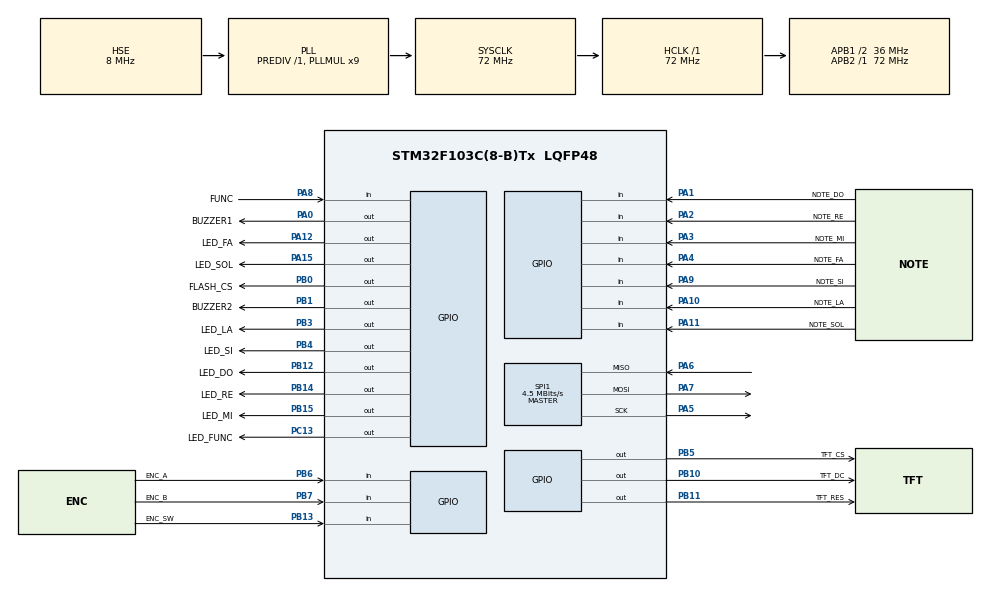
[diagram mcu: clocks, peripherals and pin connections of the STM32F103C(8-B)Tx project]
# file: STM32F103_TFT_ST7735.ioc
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Mcu.Family=STM32F1
Mcu.Name=STM32F103C(8-B)Tx
Mcu.Package=LQFP48
NVIC.PriorityGroup=NVIC_PRIORITYGROUP_4
PA5.Mode=Full_Duplex_Master
PA5.Signal=SPI1_SCK
PA6.Mode=Full_Duplex_Master
PA6.Signal=SPI1_MISO
PA7.Mode=Full_Duplex_Master
PA7.Signal=SPI1_MOSI
PA13.Mode=Serial_Wire
PA13.Signal=SYS_JTMS-SWDIO
PA14.Mode=Serial_Wire
PA14.Signal=SYS_JTCK-SWCLK
PA4.GPIO_Label=NOTE_FA
PA4.GPIO_PuPd=GPIO_PULLUP
PA4.Signal=GPIO_Input
PA1.GPIO_Label=NOTE_DO
PA1.GPIO_PuPd=GPIO_PULLUP
PA1.Signal=GPIO_Input
PA2.GPIO_Label=NOTE_RE
PA2.GPIO_PuPd=GPIO_PULLUP
PA2.Signal=GPIO_Input
PA3.GPIO_Label=NOTE_MI
PA3.GPIO_PuPd=GPIO_PULLUP
PA3.Signal=GPIO_Input
PA9.GPIO_Label=NOTE_SI
PA9.GPIO_PuPd=GPIO_PULLUP
PA9.Signal=GPIO_Input
PA10.GPIO_Label=NOTE_LA
PA10.GPIO_PuPd=GPIO_PULLUP
PA10.Signal=GPIO_Input
PB0.GPIO_Label=FLASH_CS
PB0.PinState=GPIO_PIN_SET
PB0.Signal=GPIO_Output
PB12.GPIO_Label=LED_DO
PB12.PinState=GPIO_PIN_RESET
PB12.Signal=GPIO_Output
PA0.GPIO_Label=BUZZER1
PA0.PinState=GPIO_PIN_RESET
PA0.Signal=GPIO_Output
PB1.GPIO_Label=BUZZER2
PB1.PinState=GPIO_PIN_SET
PB1.Signal=GPIO_Output
PA8.GPIO_Label=FUNC
PA8.GPIO_PuPd=GPIO_PULLUP
PA8.Signal=GPIO_Input
PB14.GPIO_Label=LED_RE
PB14.PinState=GPIO_PIN_RESET
PB14.Signal=GPIO_Output
PB15.GPIO_Label=LED_MI
PB15.PinState=GPIO_PIN_RESET
PB15.Signal=GPIO_Output
PA12.GPIO_Label=LED_FA
PA12.PinState=GPIO_PIN_RESET
PA12.Signal=GPIO_Output
PA15.GPIO_Label=LED_SOL
PA15.PinState=GPIO_PIN_RESET
PA15.Signal=GPIO_Output
PB3.GPIO_Label=LED_LA
PB3.PinState=GPIO_PIN_RESET
PB3.Signal=GPIO_Output
PB4.GPIO_Label=LED_SI
PB4.PinState=GPIO_PIN_RESET
PB4.Signal=GPIO_Output
PC13.GPIO_Label=LED_FUNC
PC13.PinState=GPIO_PIN_RESET
PC13.Signal=GPIO_Output
PB5.GPIO_Label=TFT_CS
PB5.PinState=GPIO_PIN_SET
PB5.Signal=GPIO_Output
PB10.GPIO_Label=TFT_DC
PB10.PinState=GPIO_PIN_SET
PB10.Signal=GPIO_Output
PB11.GPIO_Label=TFT_RES
PB11.PinState=GPIO_PIN_SET
PB11.Signal=GPIO_Output
PA11.GPIO_Label=NOTE_SOL
PA11.GPIO_PuPd=GPIO_PULLUP
PA11.Signal=GPIO_Input
PB6.GPIO_Label=ENC_A
PB6.GPIO_PuPd=GPIO_PULLUP
PB6.Signal=GPIO_Input
PB7.GPIO_Label=ENC_B
PB7.GPIO_PuPd=GPIO_PULLUP
PB7.Signal=GPIO_Input
PB13.GPIO_Label=ENC_SW
PB13.GPIO_PuPd=GPIO_PULLUP
PB13.Signal=GPIO_Input
PD0-OSC_IN.Mode=HSE-External-Oscillator
PD0-OSC_IN.Signal=RCC_OSC_IN
PD1-OSC_OUT.Mode=HSE-External-Oscillator
PD1-OSC_OUT.Signal=RCC_OSC_OUT
ProjectManager.HeapSize=0x200
ProjectManager.StackSize=0x400
ProjectManager.TargetToolchain=Makefile
RCC.AHBFreq_Value=72000000
RCC.APB1CLKDivider=RCC_HCLK_DIV2
RCC.APB1Freq_Value=36000000
RCC.APB1TimFreq_Value=72000000
RCC.APB2Freq_Value=72000000
RCC.APB2TimFreq_Value=72000000
RCC.HCLKFreq_Value=72000000
RCC.PLLMUL=RCC_PLL_MUL9
RCC.PLLSourceVirtual=RCC_PLLSOURCE_HSE
RCC.SYSCLKFreq_VALUE=72000000
RCC.SYSCLKSource=RCC_SYSCLKSOURCE_PLLCLK
RCC.USBFreq_Value=72000000
SPI1.BaudRatePrescaler=SPI_BAUDRATEPRESCALER_16
SPI1.CalculateBaudRate=4.5 MBits/s
SPI1.Direction=SPI_DIRECTION_2LINES
SPI1.Mode=SPI_MODE_MASTER
SPI1.VirtualType=VM_MASTER
board=custom

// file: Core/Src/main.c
/* USER CODE BEGIN Header */
/**
  ******************************************************************************
  * @file           : main.c
  * @brief          : STM32F103C8T6 + 1.8" ST7735 TFT: SmartTone UI
  ******************************************************************************
  * @attention
  *
  * Copyright (c) 2026 STMicroelectronics.
  * All rights reserved.
  *
  * This software is licensed under terms that can be found in the LICENSE file
  * in the root directory of this software component.
  * If no LICENSE file comes with this software, it is provided AS-IS.
  *
  ******************************************************************************
  */
/* USER CODE END Header */
#include "main.h"

/* USER CODE BEGIN Includes */
#include "bsp_tft.h"
#include "bsp_encoder.h"
#include "bsp_func.h"
#include "bsp_notes.h"
#include "bsp_audio_tim.h"
#include "audio.h"
#include "audio_pwm.h"
#include "ui_page.h"
#include "record.h"
#include "boot_logo.h"
#include "rhythm_game.h"
#include "melody_maker.h"
/* USER CODE END Includes */

SPI_HandleTypeDef hspi1;

void SystemClock_Config(void);
static void MX_GPIO_Init(void);
static void MX_SPI1_Init(void);

int main(void)
{

  /* MCU Configuration--------------------------------------------------------*/

  /* Reset of all peripherals, initializes the Flash interface and the Systick. */
  HAL_Init();

  /* Configure the system clock */
  SystemClock_Config();

  /* Initialize all configured peripherals */
  MX_GPIO_Init();
  MX_SPI1_Init();
  /* USER CODE BEGIN 2 */
  /* 先把背光点亮，面板上电期间状态才确定；不依赖按键。 */
  tft_backlight_init();
  tft_set_brightness(5U);
  HAL_Delay(120);   /* 等面板电源稳定，冷启动时这一步很重要 */

  if (!tft_init(&hspi1)) {
    /* 仍然失败就再降速到 1.125 MHz 重试一次 */
    __HAL_SPI_DISABLE(&hspi1);
    hspi1.Init.BaudRatePrescaler = SPI_BAUDRATEPRESCALER_64;
    (void)HAL_SPI_Init(&hspi1);
    (void)tft_init(&hspi1);
  }
  AudioTim_Init();
  Audio_Init();
  Audio_AllOff();   /* 上电保险：任何残留声部立即静音，杜绝长响 */
  bsp_notes_init();
  rhythm_game_init();
  bsp_encoder_init();
  bsp_func_init();
  record_init(&hspi1);

  /* 外设初始化完成后先显示启动图；主菜单延迟到 5 s 启动流程结束后绘制。 */
  boot_logo_start();
  /* USER CODE END 2 */

  /* Infinite loop */
  /* USER CODE BEGIN WHILE */
  while (1)
  {
    uint32_t now = HAL_GetTick();

    /* 启动图期间只推进 SysTick 计时，不扫描编码器、FUNC 或音符按键。 */
    if (boot_logo_active()) {
      if (boot_logo_tick(now)) {
        ui_page_init();
      }
      continue;
    }

    Audio_Envelope_Tick();
    Metronome_Tick();
    Song_Tick();
    Drum_Tick();
    if (!melody_maker_active() && !AudioPwm_PcmActive()) { bsp_notes_poll(now); }
    bsp_encoder_poll(now);
    bsp_func_poll(now);
    ui_page_tick(now);

    bsp_encoder_event_t event;
    while (bsp_encoder_take_event(&event)) {
      ui_page_handle_event(event);
    }
    switch (bsp_func_take_event()) {
      case BSP_FUNC_EVENT_SHORT: ui_page_handle_func();      break;
      case BSP_FUNC_EVENT_LONG:  ui_page_handle_func_long(); break;
      default: break;
    }
    /* USER CODE END WHILE */

  }
}

void SystemClock_Config(void)
{
  RCC_OscInitTypeDef RCC_OscInitStruct = {0};
  RCC_ClkInitTypeDef RCC_ClkInitStruct = {0};

  /** Initializes the RCC Oscillators according to the specified parameters
  * in the RCC_OscInitTypeDef structure.
  */
  RCC_OscInitStruct.OscillatorType = RCC_OSCILLATORTYPE_HSE;
  RCC_OscInitStruct.HSEState = RCC_HSE_ON;
  RCC_OscInitStruct.HSEPredivValue = RCC_HSE_PREDIV_DIV1;
  RCC_OscInitStruct.HSIState = RCC_HSI_ON;
  RCC_OscInitStruct.PLL.PLLState = RCC_PLL_ON;
  RCC_OscInitStruct.PLL.PLLSource = RCC_PLLSOURCE_HSE;
  RCC_OscInitStruct.PLL.PLLMUL = RCC_PLL_MUL9;
  if (HAL_RCC_OscConfig(&RCC_OscInitStruct) != HAL_OK)
  {
    Error_Handler();
  }

  /** Initializes the CPU, AHB and APB buses clocks
  */
  RCC_ClkInitStruct.ClockType = RCC_CLOCKTYPE_HCLK|RCC_CLOCKTYPE_SYSCLK
                              |RCC_CLOCKTYPE_PCLK1|RCC_CLOCKTYPE_PCLK2;
  RCC_ClkInitStruct.SYSCLKSource = RCC_SYSCLKSOURCE_PLLCLK;
  RCC_ClkInitStruct.AHBCLKDivider = RCC_SYSCLK_DIV1;
  RCC_ClkInitStruct.APB1CLKDivider = RCC_HCLK_DIV2;
  RCC_ClkInitStruct.APB2CLKDivider = RCC_HCLK_DIV1;

  if (HAL_RCC_ClockConfig(&RCC_ClkInitStruct, FLASH_LATENCY_2) != HAL_OK)
  {
    Error_Handler();
  }
}

static void MX_SPI1_Init(void)
{
  hspi1.Instance = SPI1;
  hspi1.Init.Mode = SPI_MODE_MASTER;
  hspi1.Init.Direction = SPI_DIRECTION_2LINES;
  hspi1.Init.DataSize = SPI_DATASIZE_8BIT;
  hspi1.Init.CLKPolarity = SPI_POLARITY_LOW;
  hspi1.Init.CLKPhase = SPI_PHASE_1EDGE;
  hspi1.Init.NSS = SPI_NSS_SOFT;
  hspi1.Init.BaudRatePrescaler = SPI_BAUDRATEPRESCALER_32; /* 72 MHz / 32 = 2.25 MHz，杜邦线上更稳 */
  hspi1.Init.FirstBit = SPI_FIRSTBIT_MSB;
  hspi1.Init.TIMode = SPI_TIMODE_DISABLE;
  hspi1.Init.CRCCalculation = SPI_CRCCALCULATION_DISABLE;
  hspi1.Init.CRCPolynomial = 10;
  if (HAL_SPI_Init(&hspi1) != HAL_OK)
  {
    Error_Handler();
  }
}

static void MX_GPIO_Init(void)
{
  GPIO_InitTypeDef GPIO_InitStruct = {0};

  /* GPIO Ports Clock Enable */
  __HAL_RCC_GPIOA_CLK_ENABLE();
  __HAL_RCC_GPIOB_CLK_ENABLE();
  __HAL_RCC_GPIOC_CLK_ENABLE();

  /* PA15/PB3/PB4 作为 LED，需要关闭 JTAG、保留 SWD。 */
  __HAL_AFIO_REMAP_SWJ_NOJTAG();

  /* TFT 控制脚初始为高电平，DC 在驱动内部发送命令时再拉低。 */
  HAL_GPIO_WritePin(GPIOB, TFT_CS_Pin | TFT_DC_Pin | TFT_RES_Pin, GPIO_PIN_SET);
  /* W25Q64 独立片选 PB0，空闲保持高电平。 */
  HAL_GPIO_WritePin(W25Q64_CS_GPIO_Port, W25Q64_CS_Pin, GPIO_PIN_SET);
  /* 蜂鸣器和 LED 初始关闭。 */
  HAL_GPIO_WritePin(GPIOA, BUZZER1_Pin | LED_FA_Pin | LED_SOL_Pin, GPIO_PIN_RESET);
  HAL_GPIO_WritePin(GPIOB,
                    BUZZER2_Pin | LED_DO_Pin | LED_RE_Pin | LED_MI_Pin |
                    LED_LA_Pin | LED_SI_Pin, GPIO_PIN_RESET);
  HAL_GPIO_WritePin(GPIOC, LED_FUNC_Pin, GPIO_PIN_RESET);

  /*Configure GPIO pins : TFT_CS_Pin TFT_DC_Pin TFT_RES_Pin */
  GPIO_InitStruct.Pin = TFT_CS_Pin | TFT_DC_Pin | TFT_RES_Pin;
  GPIO_InitStruct.Mode = GPIO_MODE_OUTPUT_PP;
  GPIO_InitStruct.Pull = GPIO_NOPULL;
  GPIO_InitStruct.Speed = GPIO_SPEED_FREQ_HIGH;
  HAL_GPIO_Init(GPIOB, &GPIO_InitStruct);

  /* W25Q64 片选 PB0，推挽输出，初始高电平。 */
  GPIO_InitStruct.Pin = W25Q64_CS_Pin;
  GPIO_InitStruct.Mode = GPIO_MODE_OUTPUT_PP;
  GPIO_InitStruct.Pull = GPIO_NOPULL;
  GPIO_InitStruct.Speed = GPIO_SPEED_FREQ_HIGH;
  HAL_GPIO_Init(W25Q64_CS_GPIO_Port, &GPIO_InitStruct);

  /* 两路蜂鸣器输出，初始低电平。 */
  GPIO_InitStruct.Pin = BUZZER1_Pin | LED_FA_Pin | LED_SOL_Pin;
  GPIO_InitStruct.Mode = GPIO_MODE_OUTPUT_PP;
  GPIO_InitStruct.Pull = GPIO_NOPULL;
  GPIO_InitStruct.Speed = GPIO_SPEED_FREQ_HIGH;
  HAL_GPIO_Init(GPIOA, &GPIO_InitStruct);

  GPIO_InitStruct.Pin = BUZZER2_Pin | LED_DO_Pin | LED_RE_Pin |
                        LED_MI_Pin | LED_LA_Pin | LED_SI_Pin;
  GPIO_InitStruct.Mode = GPIO_MODE_OUTPUT_PP;
  GPIO_InitStruct.Pull = GPIO_NOPULL;
  GPIO_InitStruct.Speed = GPIO_SPEED_FREQ_HIGH;
  HAL_GPIO_Init(GPIOB, &GPIO_InitStruct);

  GPIO_InitStruct.Pin = LED_FUNC_Pin;
  GPIO_InitStruct.Mode = GPIO_MODE_OUTPUT_PP;
  GPIO_InitStruct.Pull = GPIO_NOPULL;
  GPIO_InitStruct.Speed = GPIO_SPEED_FREQ_LOW;
  HAL_GPIO_Init(GPIOC, &GPIO_InitStruct);

  /* EC11 A=PB6、B=PB7、按键=PB13：上拉输入，公共端接 GND。 */
  GPIO_InitStruct.Pin = ENC_A_Pin | ENC_B_Pin | ENC_SW_Pin;
  GPIO_InitStruct.Mode = GPIO_MODE_INPUT;
  GPIO_InitStruct.Pull = GPIO_PULLUP;
  HAL_GPIO_Init(GPIOB, &GPIO_InitStruct);

  /* FUNC 按键 PA8：上拉输入，按下接地。 */
  GPIO_InitStruct.Pin = FUNC_Pin;
  GPIO_InitStruct.Mode = GPIO_MODE_INPUT;
  GPIO_InitStruct.Pull = GPIO_PULLUP;
  HAL_GPIO_Init(FUNC_GPIO_Port, &GPIO_InitStruct);

  /* 7 个音符按键：PA1/2/3/4/11/10/9，上拉输入，按下为低。 */
  GPIO_InitStruct.Pin = NOTE_DO_Pin | NOTE_RE_Pin | NOTE_MI_Pin |
                        NOTE_FA_Pin | NOTE_SOL_Pin | NOTE_LA_Pin |
                        NOTE_SI_Pin;
  GPIO_InitStruct.Mode = GPIO_MODE_INPUT;
  GPIO_InitStruct.Pull = GPIO_PULLUP;
  HAL_GPIO_Init(GPIOA, &GPIO_InitStruct);

  /* USER CODE BEGIN MX_GPIO_Init_2 */
  /* PB1 passive buzzer is active low: idle high before display initialization. */
  HAL_GPIO_WritePin(BUZZER2_GPIO_Port, BUZZER2_Pin, GPIO_PIN_SET);

  /* USER CODE END MX_GPIO_Init_2 */
}

void Error_Handler(void)
{
  __disable_irq();
  while (1)
  {
  }
}
